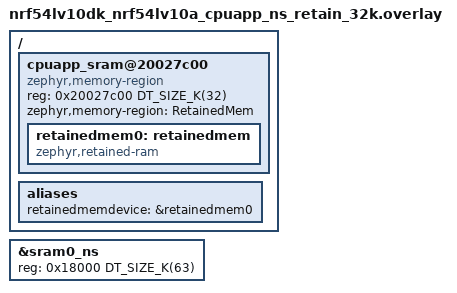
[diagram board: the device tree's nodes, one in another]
/ {
	cpuapp_sram@20027c00 {
		compatible = "zephyr,memory-region", "mmio-sram";
		reg = <0x20027c00 DT_SIZE_K(32)>;
		zephyr,memory-region = "RetainedMem";
		status = "okay";

		retainedmem0: retainedmem {
			compatible = "zephyr,retained-ram";
			status = "okay";
		};
	};

	aliases {
		retainedmemdevice = &retainedmem0;
	};
};

&sram0_ns {
	/* Shrink the non-secure SRAM to end where the retained memory region
	 * starts: 159 - 96 = 63 kB
	 */
	reg = <0x18000 DT_SIZE_K(63)>;
	ranges = <0x0 0x18000 DT_SIZE_K(63)>;
};
